# PY32T020xx register map
Vendor: Puya; Series: PY32L0; File version: 1.0.0
CPU: CM0+ r0p1, little endian, no MPU, no FPU, 4 interrupt priority bits
Registers are 32-bit, read-write, reset 0x0 unless marked. A register's access mark holds for its fields unless they carry their own. Offsets are from the block's base; [hi:lo] are bit positions; {n}, {i} and the like mark numbered series.

## COMP1 — Comparator 1
Base 0x40010200
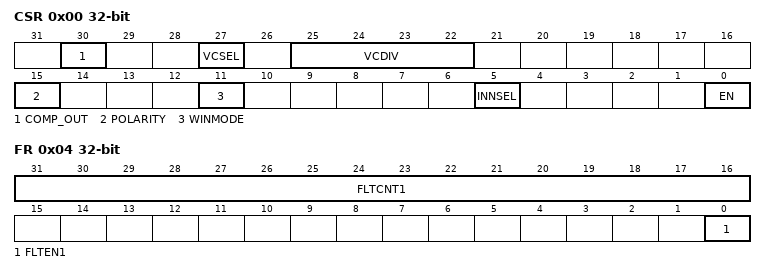
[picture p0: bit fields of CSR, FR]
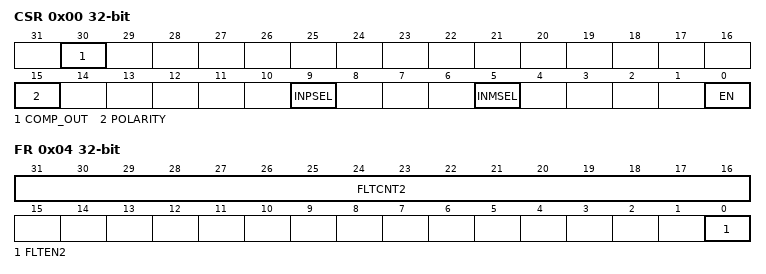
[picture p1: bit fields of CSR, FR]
0x00 CSR — COMP control and status register
  [30] COMP_OUT — Comparator output status
  [27] VCSEL
  [25:22] VCDIV
  [15] POLARITY — Comparator polarity selector
  [11] WINMODE — Comparator non-inverting input selector for window mode
  [5] INNSEL
  [0] EN — COMP enable bit
0x04 FR — Comparator Filter register
  [31:16] FLTCNT1 — Comparator filter and counter
  [0] FLTEN1 — Filter enable bit

## COMP2 — Comparator2
Base 0x40010210
0x00 CSR — COMP control and status register
  [30] COMP_OUT — Comparator output status
  [15] POLARITY — Comparator polarity selector
  [9] INPSEL — Comparator signal selector for non-inverting input
  [5] INMSEL — Comparator signal selector for inverting input INM
  [0] EN — COMP enable bit
0x04 FR — Comparator Filter register
  [31:16] FLTCNT2 — Comparator filter and counter
  [0] FLTEN2 — Filter enable bit

## CRC — CRC calculation unit
Base 0x40023000
0x00 DR reset 0xFFFFFFFF — Data register
  [31:0] DR — Data Register
0x04 IDR — Independent Data register
  [7:0] IDR
0x08 CR wo — Control register
  [0] RESET — Reset bit

## DBGMCU — Debug support
Base 0x40015800
0x00 IDCODE ro — MCU Device ID Code Register
  [31:0] REV_ID
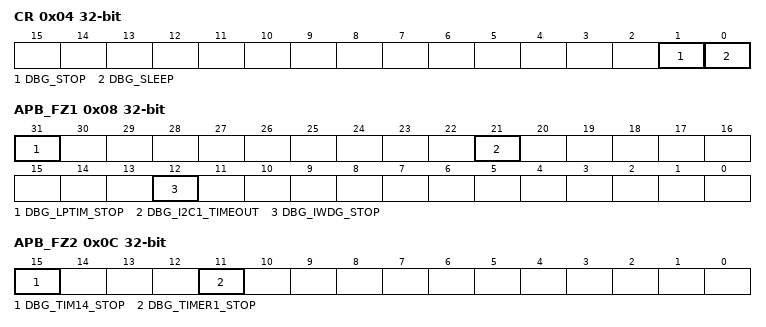
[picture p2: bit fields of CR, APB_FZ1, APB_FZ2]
0x04 CR — Debug MCU Configuration Register
  [1] DBG_STOP — Debug Stop Mode
  [0] DBG_SLEEP — Debug Sleep Mode
0x08 APB_FZ1 — APB Freeze Register1
  [31] DBG_LPTIM_STOP — Debug LPTIM stopped when Core ishalted
  [21] DBG_I2C1_TIMEOUT — Debug I2C1 TIMEOUT stopped when Core ishalted
  [12] DBG_IWDG_STOP — Debug Independent Wachdog stopped whenCore is halted
0x0C APB_FZ2 — APB Freeze Register2
  [15] DBG_TIM14_STOP — Debug TIM 14 stopped whenCore is halted
  [11] DBG_TIMER1_STOP — Debug Timer 1 stopped when Core ishalted

## EXTI — External interrupt/event controller
Base 0x40021800
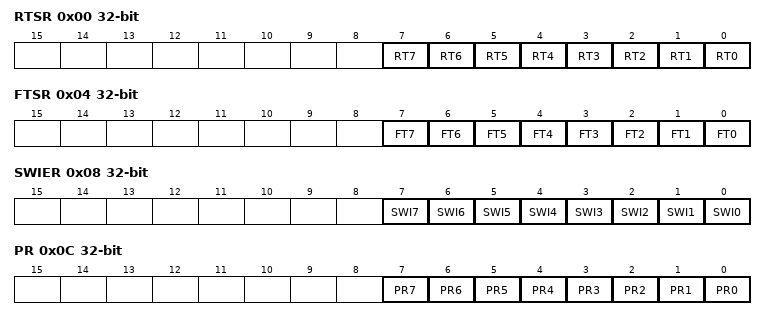
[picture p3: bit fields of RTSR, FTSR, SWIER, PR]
0x00 RTSR — EXTI rising trigger selection register
  [n] RT{n} (n=0..7) — Rising trigger event configuration bit of Configurable Event input
0x04 FTSR — EXTI falling trigger selection register
  [n] FT{n} (n=0..7) — Falling trigger event configuration bit of Configurable Event input
0x08 SWIER — EXTI software interrupt event register
  [n] SWI{n} (n=0..7) — Rising trigger event configuration bit of Configurable Event input
0x0C PR — EXTI pending register
  [n] PR{n} (n=0..7) — configurable event inputs x rising edge Pending bit.
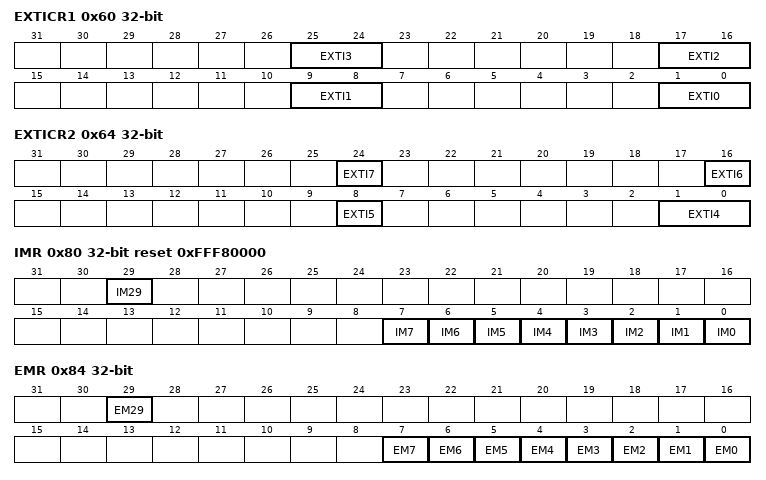
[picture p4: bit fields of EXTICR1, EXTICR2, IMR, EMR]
0x60 EXTICR1 — EXTI external interrupt selection register
  [8n+1:8n] EXTI{n} (n=0..3) — GPIO port selection
0x64 EXTICR2 — EXTI external interrupt selection register
  [24] EXTI7 — GPIO port selection
  [16] EXTI6 — GPIO port selection
  [8] EXTI5 — GPIO port selection
  [1:0] EXTI4 — GPIO port selection
0x80 IMR reset 0xFFF80000 — EXTI CPU wakeup with interrupt mask register
  [29] IM29 — CPU wakeup with interrupt mask on event input
  [n] IM{n} (n=0..7) — CPU wakeup with interrupt mask on event input
0x84 EMR — EXTI CPU wakeup with event mask register
  [29] EM29 — CPU wakeup with event mask on event input
  [n] EM{n} (n=0..7) — CPU wakeup with event mask on event input

## FLASH
Base 0x40022000
0x00 ACR
  [1:0] LATENCY
0x08 KEY
  [31:0] KEY wo — Flash CR key
0x0C OPTKEY
  [31:0] OPTKEY wo — Flash Option key
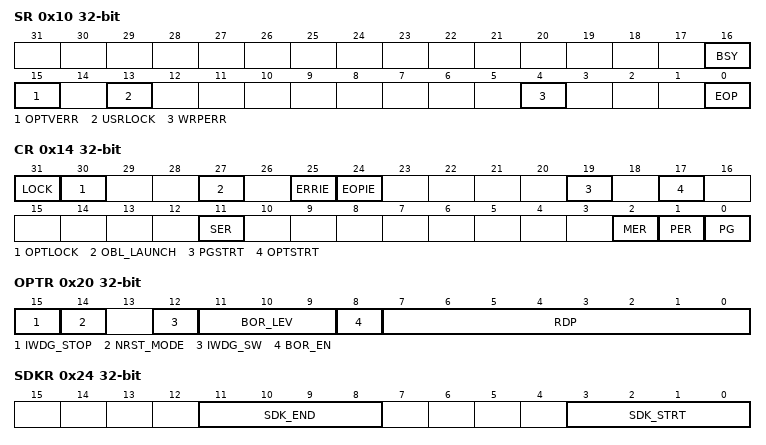
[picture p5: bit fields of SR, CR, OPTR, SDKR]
0x10 SR
  [16] BSY ro — Busy
  [15] OPTVERR — Option and trimming bits loading validity error
  [13] USRLOCK ro — Userdata Lock
  [4] WRPERR — Write protection error
  [0] EOP — End of operation
0x14 CR
  [31] LOCK
  [30] OPTLOCK — Option Lock
  [27] OBL_LAUNCH — Force the option bytes loading
  [25] ERRIE — Error interrupt enable
  [24] EOPIE — End of operation interrupt enable
  [19] PGSTRT — Programming Start
  [17] OPTSTRT — Option bytes Programming Start
  [11] SER — Sector Erase
  [2] MER — Mass Erase
  [1] PER — Page Erase
  [0] PG — Page Program
0x20 OPTR
  [15] IWDG_STOP — IWDG Counting enable in Stop Mode
  [14] NRST_MODE — Pin n_reset Mode
  [12] IWDG_SW — IWDG Software Enable
  [11:9] BOR_LEV — BOR Level
  [8] BOR_EN — BOR enable
  [7:0] RDP — Read Protection
0x24 SDKR
  [11:8] SDK_END — SDK Area End Address
  [3:0] SDK_STRT — SDK Area Start Address
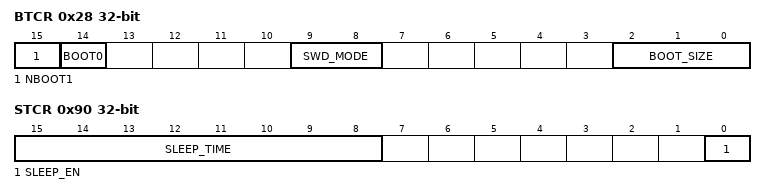
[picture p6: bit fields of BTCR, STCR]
0x28 BTCR
  [15] NBOOT1
  [14] BOOT0
  [9:8] SWD_MODE
  [2:0] BOOT_SIZE — Load Flash Size
0x2C WRPR
  [7:0] WRP — Write Protection Disable
0x90 STCR
  [15:8] SLEEP_TIME — FLASH Sleep Time Configuration
  [0] SLEEP_EN — FLASH Sleep Enable
0x120 PRETPE
